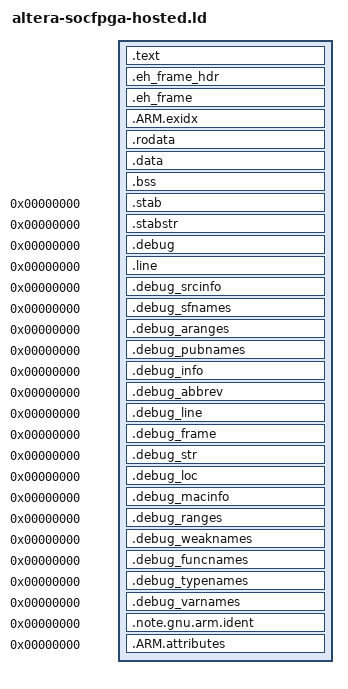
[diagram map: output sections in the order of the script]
/* Specify the output format and the entry point */
OUTPUT_FORMAT("elf32-littlearm", "elf32-bigarm", "elf32-littlearm")
ENTRY(_start)
SEARCH_DIR(.)

GROUP(-lgcc -lc)

SECTIONS
{
  /* Text (code) section starts at arm_program_mem */
  . = arm_program_mem;

  .text :
  {
    CREATE_OBJECT_SYMBOLS
    __cs3_region_start_ram = .;
    _ftext = .;
    *(.cs3.region-head.ram)
    ASSERT (. == __cs3_region_start_ram, ".cs3.region-head.ram not permitted");
    /* __cs3_interrupt_vector = __cs3_interrupt_vector_arm; */
    *(.cs3.interrupt_vector)
    /* Ensure interrupt vector is present */
    /* ASSERT (. != __cs3_interrupt_vector_arm, "No interrupt vector"); */

    PROVIDE(__cs3_reset = __cs3_reset_generic);
    *(.cs3.reset)
    _start = DEFINED(__cs3_start_asm) ? __cs3_start_asm : _start;

    *(.text.cs3.init)
    *(.text .text.* .gnu.linkonce.t.*)
    *(.plt)
    *(.gnu.warning)
    *(.glue_7t) *(.glue_7) *(.vfp11_veneer)

    *(.ARM.extab* .gnu.linkonce.armextab.*)
    *(.gcc_except_table)
  }

  .eh_frame_hdr : ALIGN (4)
  {
    KEEP (*(.eh_frame_hdr))
    *(.eh_frame_entry .eh_frame_entry.*)
  }

  .eh_frame : ALIGN (4)
  {
    KEEP (*(.eh_frame))
    *(.eh_frame.*)
  }

  /* Exception index section */
  PROVIDE_HIDDEN (__exidx_start = .);
  .ARM.exidx :
  {
    *(.ARM.exidx* .gnu.linkonce.armexidx.*)
  }
  PROVIDE_HIDDEN (__exidx_end = .);

  /* Read-only data section */
  .rodata : ALIGN (4)
  {
    *(.rodata .rodata.* .gnu.linkonce.r.*)

    . = ALIGN(4);
    KEEP(*(.init))

    . = ALIGN(4);
    __preinit_array_start = .;
    KEEP (*(.preinit_array))
    __preinit_array_end = .;

    . = ALIGN(4);
    __init_array_start = .;
    KEEP (*(SORT(.init_array.*)))
    KEEP (*(.init_array))
    __init_array_end = .;

    . = ALIGN(4);
    KEEP(*(.fini))

    . = ALIGN(4);
    __fini_array_start = .;
    KEEP (*(.fini_array))
    KEEP (*(SORT(.fini_array.*)))
    __fini_array_end = .;

    . = ALIGN(0x4);
    KEEP (*crtbegin.o(.ctors))
    KEEP (*(EXCLUDE_FILE (*crtend.o) .ctors))
    KEEP (*(SORT(.ctors.*)))
    KEEP (*crtend.o(.ctors))

    . = ALIGN(0x4);
    KEEP (*crtbegin.o(.dtors))
    KEEP (*(EXCLUDE_FILE (*crtend.o) .dtors))
    KEEP (*(SORT(.dtors.*)))
    KEEP (*crtend.o(.dtors))

    . = ALIGN(4);
    __cs3_regions = .;
    LONG (0)
    LONG (__cs3_region_init_ram)
    LONG (__cs3_region_start_ram)
    LONG (__cs3_region_init_size_ram)
    LONG (__cs3_region_zero_size_ram)
    __cs3_regions_end = .;
    . = ALIGN (8);
    _etext = .;
  }

  /* Data section (for initialized variables) */
  .data : ALIGN (8)
  {
    KEEP(*(.jcr))
    *(.got.plt) *(.got)
    *(.shdata)
    *(.data .data.* .gnu.linkonce.d.*)
    . = ALIGN (8);
    *(.ram)
    . = ALIGN (8);
    _edata = .;
  }

  /* BSS section (for uninitialized variables) */
  .bss : ALIGN (8)
  {
    __bss_start__ = .;
    *(.shbss)
    *(.bss .bss.* .gnu.linkonce.b.*)
    *(COMMON)
    . = ALIGN (8);
    __bss_end__ = .;
    _end = .;
  }

  /* Define memory regions */
  __cs3_region_end_ram = __cs3_region_start_ram + arm_available_mem_size;
  __cs3_region_size_ram = arm_available_mem_size;
  __cs3_region_init_ram = LOADADDR (.text);
  __cs3_region_init_size_ram = _edata - ADDR (.text);
  __cs3_region_zero_size_ram = _end - _edata;

  /* Debugging and stack handling */
  .stab 0 (NOLOAD) : { *(.stab) }
  .stabstr 0 (NOLOAD) : { *(.stabstr) }

  /* DWARF debug sections */
  .debug          0 : { *(.debug) }
  .line           0 : { *(.line) }
  .debug_srcinfo  0 : { *(.debug_srcinfo) }
  .debug_sfnames  0 : { *(.debug_sfnames) }
  .debug_aranges  0 : { *(.debug_aranges) }
  .debug_pubnames 0 : { *(.debug_pubnames) }
  .debug_info     0 : { *(.debug_info .gnu.linkonce.wi.*) }
  .debug_abbrev   0 : { *(.debug_abbrev) }
  .debug_line     0 : { *(.debug_line) }
  .debug_frame    0 : { *(.debug_frame) }
  .debug_str      0 : { *(.debug_str) }
  .debug_loc      0 : { *(.debug_loc) }
  .debug_macinfo  0 : { *(.debug_macinfo) }
  .debug_ranges   0 : { *(.debug_ranges) }
  .debug_weaknames 0 : { *(.debug_weaknames) }
  .debug_funcnames 0 : { *(.debug_funcnames) }
  .debug_typenames 0 : { *(.debug_typenames) }
  .debug_varnames  0 : { *(.debug_varnames) }

  /* ARM-specific attributes */
  .note.gnu.arm.ident 0 : { KEEP (*(.note.gnu.arm.ident)) }
  .ARM.attributes 0 : { KEEP (*(.ARM.attributes)) }
  /DISCARD/ : { *(.note.GNU-stack) }
}
